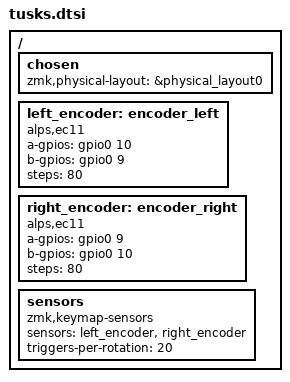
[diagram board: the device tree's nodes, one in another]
#include <dt-bindings/zmk/matrix_transform.h>
#include "tusks-layouts.dtsi"
/ {

	chosen {
        zmk,physical-layout = &physical_layout0;
	};

	left_encoder: encoder_left {
		compatible = "alps,ec11";
		a-gpios = <&gpio0 10 (GPIO_ACTIVE_HIGH | GPIO_PULL_UP)>;
		b-gpios = <&gpio0 9 (GPIO_ACTIVE_HIGH | GPIO_PULL_UP)>;
		steps = <80>;
	};

	right_encoder: encoder_right {
		compatible = "alps,ec11";
		a-gpios = <&gpio0 9 (GPIO_ACTIVE_HIGH | GPIO_PULL_UP)>;
		b-gpios = <&gpio0 10 (GPIO_ACTIVE_HIGH | GPIO_PULL_UP)>;
		steps = <80>;
	};

	sensors: sensors {
		compatible = "zmk,keymap-sensors";
		sensors = <&left_encoder &right_encoder>;
		triggers-per-rotation = <20>;
	};
};
